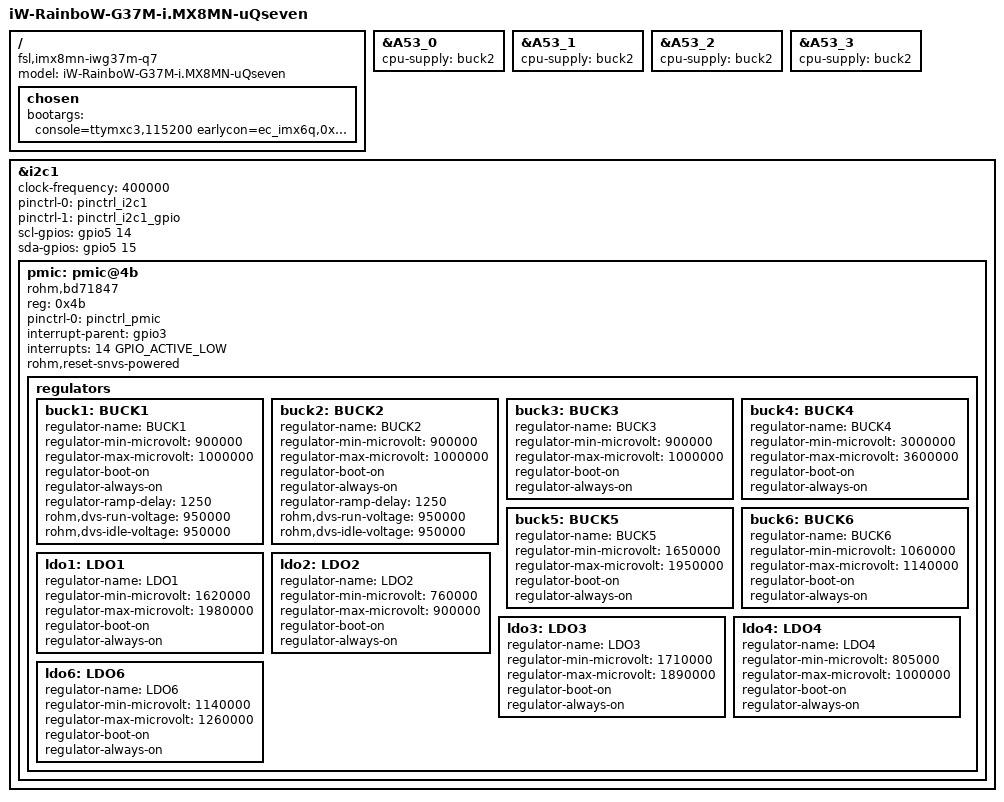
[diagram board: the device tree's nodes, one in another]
// SPDX-License-Identifier: (GPL-2.0+ OR MIT)
/*
 * Copyright 2022 iWave Systems Technologies Pvt Ltd.
 */

/dts-v1/;

#include "imx8mn.dtsi"
#include "imx8mn-iwg37m-q7.dtsi"
#include <dt-bindings/interrupt-controller/irq.h>

/ {
	model = "iW-RainboW-G37M-i.MX8MN-uQseven";
	compatible = "fsl,imx8mn-iwg37m-q7", "fsl,imx8mn";

	chosen {
		bootargs = "console=ttymxc3,115200 earlycon=ec_imx6q,0x30a60000,115200";
	};
};

&A53_0 {
	cpu-supply = <&buck2>;
};

&A53_1 {
	cpu-supply = <&buck2>;
};

&A53_2 {
	cpu-supply = <&buck2>;
};

&A53_3 {
	cpu-supply = <&buck2>;
};

&i2c1 {
	clock-frequency = <400000>;
	pinctrl-names = "default", "gpio";
	pinctrl-0 = <&pinctrl_i2c1>;
	pinctrl-1 = <&pinctrl_i2c1_gpio>;
	scl-gpios = <&gpio5 14 GPIO_ACTIVE_HIGH>;
	sda-gpios = <&gpio5 15 GPIO_ACTIVE_HIGH>;
	status = "okay";
	pmic: pmic@4b {
		compatible = "rohm,bd71847";
		reg = <0x4b>;
		pinctrl-0 = <&pinctrl_pmic>;
		interrupt-parent = <&gpio3>;
		interrupts = <14 GPIO_ACTIVE_LOW>;
		rohm,reset-snvs-powered;

		regulators {
			buck1: BUCK1 {
				regulator-name = "BUCK1";
				regulator-min-microvolt = <900000>;
				regulator-max-microvolt = <1000000>;
				regulator-boot-on;
				regulator-always-on;
				regulator-ramp-delay = <1250>;
                                rohm,dvs-run-voltage = <950000>;
                                rohm,dvs-idle-voltage = <950000>;
			};

			buck2: BUCK2 {
				regulator-name = "BUCK2";
				regulator-min-microvolt = <900000>;
				regulator-max-microvolt = <1000000>;
				regulator-boot-on;
				regulator-always-on;
				regulator-ramp-delay = <1250>;
				rohm,dvs-run-voltage = <950000>;
				rohm,dvs-idle-voltage = <950000>;
			};

			buck3: BUCK3 {
				// BUCK5 in datasheet
				regulator-name = "BUCK3";
				regulator-min-microvolt = <900000>;
				regulator-max-microvolt = <1000000>;
				regulator-boot-on;
				regulator-always-on;
			};

			buck4: BUCK4 {
				// BUCK6 in datasheet
				regulator-name = "BUCK4";
				regulator-min-microvolt = <3000000>;
				regulator-max-microvolt = <3600000>;
				regulator-boot-on;
				regulator-always-on;
			};

			buck5: BUCK5 {
				// BUCK7 in datasheet
				regulator-name = "BUCK5";
				regulator-min-microvolt = <1650000>;
				regulator-max-microvolt = <1950000>;
				regulator-boot-on;
				regulator-always-on;
			};

			buck6: BUCK6 {
				// BUCK8 in datasheet
				regulator-name = "BUCK6";
				regulator-min-microvolt = <1060000>;
				regulator-max-microvolt = <1140000>;
				regulator-boot-on;
				regulator-always-on;
			};

			ldo1: LDO1 {
				regulator-name = "LDO1";
				regulator-min-microvolt = <1620000>;
				regulator-max-microvolt = <1980000>;
				regulator-boot-on;
				regulator-always-on;
			};

			ldo2: LDO2 {
				regulator-name = "LDO2";
				regulator-min-microvolt = <760000>;
				regulator-max-microvolt = <900000>;
				regulator-boot-on;
				regulator-always-on;
			};

			ldo3: LDO3 {
				regulator-name = "LDO3";
				regulator-min-microvolt = <1710000>;
				regulator-max-microvolt = <1890000>;
				regulator-boot-on;
				regulator-always-on;
			};

			ldo4: LDO4 {
				regulator-name = "LDO4";
				regulator-min-microvolt = <805000>;
				regulator-max-microvolt = <1000000>;
				regulator-boot-on;
				regulator-always-on;
			};

			ldo6: LDO6 {
				regulator-name = "LDO6";
				regulator-min-microvolt = <1140000>;
				regulator-max-microvolt = <1260000>;
				regulator-boot-on;
				regulator-always-on;
			};
		};
	};
};
